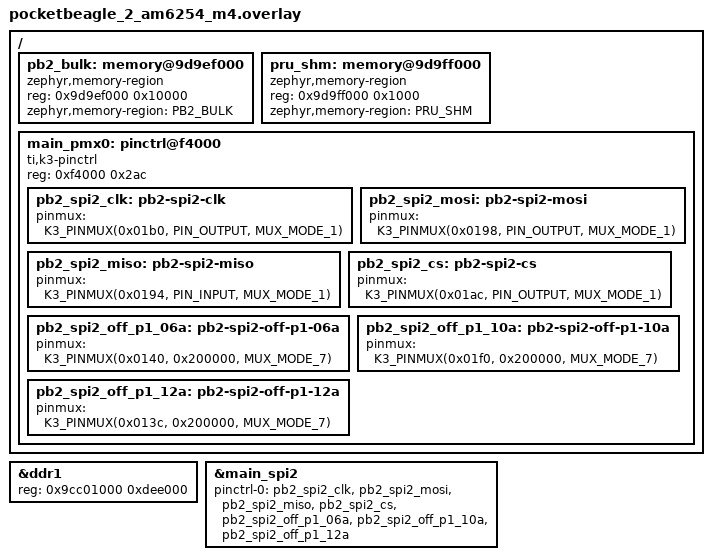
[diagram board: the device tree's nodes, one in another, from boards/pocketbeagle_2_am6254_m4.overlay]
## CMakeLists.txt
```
cmake_minimum_required(VERSION 3.20.0)

find_package(Zephyr REQUIRED HINTS $ENV{ZEPHYR_BASE})

project(pb2_m4 C CXX)

# EmbeddedRPC 1.14.0, cloned by build.sh. It is not used as a Zephyr module:
# that module's Kconfig selects SERIAL from a symbol that depends on the full
# C++ library, and the loop fails configuration. The library sources are
# compiled here,
# with erpc_malloc/erpc_free on the Zephyr heap. Transport is the existing
# OpenAMP RPMsg endpoint, not the module's UART or RPMsg-Lite ports.
set(ERPC ${CMAKE_CURRENT_LIST_DIR}/../../third_party/erpc/erpc_c)

target_include_directories(app PRIVATE
  ${CMAKE_CURRENT_SOURCE_DIR}/../include
  ${CMAKE_CURRENT_SOURCE_DIR}/../erpc/shim
  ${CMAKE_CURRENT_SOURCE_DIR}/src
  ${ERPC}/infra
  ${ERPC}/port
  ${ERPC}/setup
  ${LIBMETAL_INCLUDE_DIR}
  ${OPENAMP_INCLUDE_DIR}
  ${PLATFORM_DIR}
)

target_sources(app PRIVATE
  src/main.c
  src/pb2_service.c
  src/pb2_erpc.cpp
  src/erpc_port_zephyr.cpp
  ../erpc/shim/c_pb2_server.cpp
  ../erpc/shim/pb2_server.cpp
  ../erpc/shim/pb2_interface.cpp
  ${ERPC}/infra/erpc_basic_codec.cpp
  ${ERPC}/infra/erpc_crc16.cpp
  ${ERPC}/infra/erpc_framed_transport.cpp
  ${ERPC}/infra/erpc_message_buffer.cpp
  ${ERPC}/infra/erpc_message_loggers.cpp
  ${ERPC}/infra/erpc_pre_post_action.cpp
  ${ERPC}/infra/erpc_server.cpp
  ${ERPC}/infra/erpc_simple_server.cpp
  ${ERPC}/infra/erpc_utils.cpp
  ${ERPC}/setup/erpc_server_setup.cpp
  ${ERPC}/setup/erpc_setup_mbf_dynamic.cpp
)
```

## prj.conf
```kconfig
CONFIG_KERNEL_BIN_NAME="pb2_m4"
CONFIG_IPM=y
CONFIG_MBOX=y
CONFIG_CPP=y
CONFIG_STD_CPP17=y
CONFIG_REQUIRES_FULL_LIBCPP=y
CONFIG_GLIBCXX_LIBCPP=y
CONFIG_MAIN_STACK_SIZE=2048
CONFIG_HEAP_MEM_POOL_SIZE=8192
CONFIG_SYSTEM_WORKQUEUE_STACK_SIZE=2048
CONFIG_OPENAMP=y
CONFIG_OPENAMP_RSC_TABLE=y
CONFIG_OPENAMP_MASTER=n
CONFIG_OPENAMP_RSC_TABLE_NUM_RPMSG_BUFF=8
CONFIG_LOG=y
CONFIG_LOG_DEFAULT_LEVEL=3
CONFIG_SPI=y
```

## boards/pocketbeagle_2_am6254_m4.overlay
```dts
// SPDX-License-Identifier: MIT
#include <zephyr/dt-bindings/pinctrl/ti-k3-pinctrl.h>

/*
 * Carve the bulk chunk region and the small PRU mailbox out of M4 DDR.
 * ddr1 starts at 0x9cc01000. Bulk is 64 KiB at 0x9d9ef000.
 * Mailbox stays at 0x9d9ff000, matching PB2_SHM_ADDR.
 * Original ddr1 size 0xdff000 ended at 0x9da00000.
 */

&ddr1 {
	reg = <0x9cc01000 0xdee000>;
};

/ {
	pb2_bulk: memory@9d9ef000 {
		compatible = "zephyr,memory-region", "mmio-sram";
		reg = <0x9d9ef000 0x10000>;
		zephyr,memory-region = "PB2_BULK";
	};

	pru_shm: memory@9d9ff000 {
		compatible = "zephyr,memory-region", "mmio-sram";
		reg = <0x9d9ff000 0x1000>;
		zephyr,memory-region = "PRU_SHM";
	};

	/*
	 * Main padcfg at 0xf4000. One pin per group: the K3 pinctrl helper
	 * applies only the first two pinmux cells of each group.
	 * 0x200000 is the pad disable bit used by the Debian kernel's
	 * PIN_DISABLE, OR mux mode 7, so a shorted partner ball stays off.
	 */
	main_pmx0: pinctrl@f4000 {
		compatible = "ti,k3-pinctrl";
		reg = <0xf4000 0x2ac>;
		status = "okay";

		pb2_spi2_clk: pb2-spi2-clk {
			/* P1.08 A20 SPI2_CLK, mode 1 */
			pinmux = <K3_PINMUX(0x01b0, PIN_OUTPUT, MUX_MODE_1)>;
		};
		pb2_spi2_mosi: pb2-spi2-mosi {
			/* P1.12 A19 SPI2_D1 MOSI, mode 1 */
			pinmux = <K3_PINMUX(0x0198, PIN_OUTPUT, MUX_MODE_1)>;
		};
		pb2_spi2_miso: pb2-spi2-miso {
			/* P1.10 B19 SPI2_D0 MISO, mode 1 */
			pinmux = <K3_PINMUX(0x0194, PIN_INPUT, MUX_MODE_1)>;
		};
		pb2_spi2_cs: pb2-spi2-cs {
			/* P1.06 E19 SPI2_CS0, mode 1 */
			pinmux = <K3_PINMUX(0x01ac, PIN_OUTPUT, MUX_MODE_1)>;
		};
		pb2_spi2_off_p1_06a: pb2-spi2-off-p1-06a {
			/* P1.06A AD18, shorted to P1.06 */
			pinmux = <K3_PINMUX(0x0140, 0x200000, MUX_MODE_7)>;
		};
		pb2_spi2_off_p1_10a: pb2-spi2-off-p1-10a {
			/* P1.10 A18, shorted to P1.10 ball B19 */
			pinmux = <K3_PINMUX(0x01f0, 0x200000, MUX_MODE_7)>;
		};
		pb2_spi2_off_p1_12a: pb2-spi2-off-p1-12a {
			/* P1.12A AE18, shorted to P1.12 */
			pinmux = <K3_PINMUX(0x013c, 0x200000, MUX_MODE_7)>;
		};
	};
};

&main_spi2 {
	pinctrl-names = "default";
	pinctrl-0 = <&pb2_spi2_clk &pb2_spi2_mosi &pb2_spi2_miso &pb2_spi2_cs
		     &pb2_spi2_off_p1_06a &pb2_spi2_off_p1_10a &pb2_spi2_off_p1_12a>;
	status = "okay";
};
```

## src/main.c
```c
/*
 * Zephyr on the PocketBeagle 2 M4.
 *
 * Linux calls Zephyr functions over eRPC on RPMsg (channel "rpmsg-raw",
 * address 1024). armPru1 publishes a command in the DDR mailbox at
 * PB2_SHM_ADDR. PRU0 polls that mailbox and arms PRU1.
 */

#include <zephyr/kernel.h>
#include <zephyr/device.h>
#include <zephyr/drivers/ipm.h>
#include <zephyr/drivers/spi.h>
#include <zephyr/sys/printk.h>
#include <zephyr/sys/barrier.h>
#include <zephyr/cache.h>
#include <zephyr/logging/log.h>

#include <errno.h>

#include <openamp/open_amp.h>
#include <metal/sys.h>
#include <metal/io.h>
#include <resource_table.h>
#include <addr_translation.h>

#include "pb2_shm.h"
#include "pb2_erpc.h"

LOG_MODULE_REGISTER(pb2_m4, LOG_LEVEL_INF);

#define RPMSG_CHAN_NAME "rpmsg-raw"
#define RPMSG_CHAN_ADDR 1024

#if CONFIG_IPM_MAX_DATA_SIZE > 0
#define IPM_SEND(dev, w, id, d, s) ipm_send(dev, w, id, d, s)
#else
#define IPM_SEND(dev, w, id, d, s) ipm_send(dev, w, id, NULL, 0)
#endif

#define SHM_NODE       DT_CHOSEN(zephyr_ipc_shm)
#define SHM_START_ADDR DT_REG_ADDR(SHM_NODE)
#define SHM_SIZE       DT_REG_SIZE(SHM_NODE)

#if !DT_HAS_CHOSEN(zephyr_ipc_shm)
#error "M4 board must choose zephyr,ipc_shm"
#endif

static const struct device *const ipm_handle = DEVICE_DT_GET(DT_CHOSEN(zephyr_ipc));

static metal_phys_addr_t shm_physmap = SHM_START_ADDR;
static metal_phys_addr_t rsc_tab_physmap;
static struct metal_io_region shm_io_data;
static struct metal_io_region rsc_io_data;
static struct metal_io_region *shm_io = &shm_io_data;
static struct metal_io_region *rsc_io = &rsc_io_data;
static struct rpmsg_virtio_device rvdev;
static struct rpmsg_device *rpdev;
static struct rpmsg_endpoint ept;
static void *rsc_table;

static K_SEM_DEFINE(mb_sem, 0, 1);

static uint32_t shm_seq;

static volatile struct pb2_shm *const pru_shm =
	(volatile struct pb2_shm *)PB2_SHM_ADDR;

void pb2_shm_publish(const char *cmd)
{
	size_t n = strlen(cmd);

	if (n > sizeof(pru_shm->cmd) - 1) {
		n = sizeof(pru_shm->cmd) - 1;
	}
	memcpy((void *)pru_shm->cmd, cmd, n);
	((volatile char *)pru_shm->cmd)[n] = '\0';
	pru_shm->magic = PB2_SHM_MAGIC;
	barrier_dmem_fence_full();
	pru_shm->seq = ++shm_seq;
	barrier_dmem_fence_full();
	sys_cache_data_flush_range((void *)pru_shm, sizeof(*pru_shm));
	LOG_INF("shm seq %u cmd %s", shm_seq, cmd);
}

static void platform_ipm_callback(const struct device *dev, void *context,
				  uint32_t id, volatile void *data)
{
	ARG_UNUSED(dev);
	ARG_UNUSED(context);
	ARG_UNUSED(id);
	ARG_UNUSED(data);
	k_sem_give(&mb_sem);
}

static int mailbox_notify(void *priv, uint32_t id)
{
	ARG_UNUSED(priv);
	IPM_SEND(ipm_handle, 0, id, &id, 4);
	return 0;
}

static int platform_init(void)
{
	struct metal_init_params metal_params = METAL_INIT_DEFAULTS;
	int rsc_size;
	int status;

	status = metal_init(&metal_params);
	if (status) {
		LOG_ERR("metal_init failed: %d", status);
		return -1;
	}

	metal_io_init(shm_io, (void *)SHM_START_ADDR, &shm_physmap, SHM_SIZE,
		      -1, 0, addr_translation_get_ops(shm_physmap));

	rsc_table_get(&rsc_table, &rsc_size);
	rsc_tab_physmap = (uintptr_t)rsc_table;
	metal_io_init(rsc_io, rsc_table, &rsc_tab_physmap, rsc_size, -1, 0, NULL);

	if (!device_is_ready(ipm_handle)) {
		LOG_ERR("IPM device is not ready");
		return -1;
	}
	ipm_register_callback(ipm_handle, platform_ipm_callback, NULL);
	status = ipm_set_enabled(ipm_handle, 1);
	if (status) {
		LOG_ERR("ipm_set_enabled failed");
		return -1;
	}
	return 0;
}

static struct rpmsg_device *platform_create_rpmsg_vdev(void)
{
	struct fw_rsc_vdev_vring *vring_rsc;
	struct virtio_device *vdev;
	int ret;

	vdev = rproc_virtio_create_vdev(VIRTIO_DEV_DEVICE, VDEV_ID,
					rsc_table_to_vdev(rsc_table),
					rsc_io, NULL, mailbox_notify, NULL);
	if (!vdev) {
		LOG_ERR("failed to create vdev");
		return NULL;
	}

	rproc_virtio_wait_remote_ready(vdev);

	vring_rsc = rsc_table_get_vring0(rsc_table);
	ret = rproc_virtio_init_vring(vdev, 0, vring_rsc->notifyid,
				      (void *)vring_rsc->da, rsc_io,
				      vring_rsc->num, vring_rsc->align);
	if (ret) {
		LOG_ERR("failed to init vring 0");
		goto failed;
	}

	vring_rsc = rsc_table_get_vring1(rsc_table);
	ret = rproc_virtio_init_vring(vdev, 1, vring_rsc->notifyid,
				      (void *)vring_rsc->da, rsc_io,
				      vring_rsc->num, vring_rsc->align);
	if (ret) {
		LOG_ERR("failed to init vring 1");
		goto failed;
	}

	ret = rpmsg_init_vdev(&rvdev, vdev, NULL, shm_io, NULL);
	if (ret) {
		LOG_ERR("failed rpmsg_init_vdev");
		goto failed;
	}
	return rpmsg_virtio_get_rpmsg_device(&rvdev);

failed:
	rproc_virtio_remove_vdev(vdev);
	return NULL;
}

static int rx_cb(struct rpmsg_endpoint *ept_dev, void *data, size_t len,
		 uint32_t src, void *priv)
{
	ARG_UNUSED(ept_dev);
	ARG_UNUSED(src);
	ARG_UNUSED(priv);

	pb2_erpc_push(data, len);
	return RPMSG_SUCCESS;
}

int pb2_rpmsg_tx(const void *data, size_t len)
{
	int ret = rpmsg_send(&ept, (void *)data, len);

	return ret < 0 ? -1 : 0;
}

static void app_thread(void *a, void *b, void *c)
{
	ARG_UNUSED(a);
	ARG_UNUSED(b);
	ARG_UNUSED(c);

	pb2_erpc_server();
}

static void rpmsg_thread(void *a, void *b, void *c)
{
	ARG_UNUSED(a);
	ARG_UNUSED(b);
	ARG_UNUSED(c);

	if (platform_init()) {
		return;
	}
	rpdev = platform_create_rpmsg_vdev();
	if (!rpdev) {
		return;
	}

	if (rpmsg_create_ept(&ept, rpdev, RPMSG_CHAN_NAME, RPMSG_CHAN_ADDR,
			     RPMSG_ADDR_ANY, rx_cb, NULL)) {
		LOG_ERR("rpmsg_create_ept failed");
		return;
	}
	LOG_INF("rpmsg channel %s addr %d is up", RPMSG_CHAN_NAME, RPMSG_CHAN_ADDR);

	while (1) {
		k_sem_take(&mb_sem, K_FOREVER);
		rproc_virtio_notified(rvdev.vdev, VRING1_ID);
	}
}

K_THREAD_DEFINE(rpmsg_tid, 4096, rpmsg_thread, NULL, NULL, NULL, K_PRIO_COOP(8), 0, 0);
K_THREAD_DEFINE(app_tid, 8192, app_thread, NULL, NULL, NULL, K_PRIO_COOP(7), 0, 0);

int pb2_spi2_write(const void *buf, size_t len)
{
	static const struct spi_config cfg = {
		.frequency = 1000000,
		.operation = SPI_OP_MODE_MASTER | SPI_WORD_SET(8) | SPI_TRANSFER_MSB,
		.peripheral = 0,
	};
	const struct device *spi = DEVICE_DT_GET(DT_NODELABEL(main_spi2));
	const struct spi_buf txb = {
		.buf = (void *)buf,
		.len = len,
	};
	const struct spi_buf_set tx = {
		.buffers = &txb,
		.count = 1,
	};

	if (!buf || !len) {
		return -EINVAL;
	}
	if (!device_is_ready(spi)) {
		LOG_ERR("spi2 not ready");
		return -ENODEV;
	}
	return spi_write(spi, &cfg, &tx);
}

static void pb2_spi_hello(void)
{
	static const uint8_t hello[] = {'h', 'e', 'l', 'l', 'o'};
	int ret = pb2_spi2_write(hello, sizeof(hello));
	char msg[56];

	if (ret == -ENODEV) {
		pb2_shm_publish("spi hello not ready");
		return;
	}
	if (ret) {
		LOG_ERR("spi2 hello failed: %d", ret);
		snprintk(msg, sizeof(msg), "spi hello fail %d", ret);
		pb2_shm_publish(msg);
		return;
	}
	LOG_INF("spi2 hello wrote %u bytes", (unsigned int)sizeof(hello));
	pb2_shm_publish("spi hello ok");
}

int main(void)
{
	pb2_shm_publish("hello from zephyr");
	LOG_INF("pb2 m4 hello, shm seq %u", shm_seq);
	pb2_spi_hello();
	return 0;
}
```

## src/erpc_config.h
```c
/* SPDX-License-Identifier: MIT */
#ifndef _ERPC_CONFIG_H_
#define _ERPC_CONFIG_H_

#define ERPC_ALLOCATION_POLICY_DYNAMIC (0U)
#define ERPC_ALLOCATION_POLICY_STATIC (1U)
#define ERPC_THREADS_NONE (0U)
#define ERPC_THREADS_PTHREADS (1U)
#define ERPC_THREADS_FREERTOS (2U)
#define ERPC_THREADS_ZEPHYR (3U)
#define ERPC_THREADS_MBED (4U)
#define ERPC_THREADS_WIN32 (5U)
#define ERPC_THREADS_THREADX (6U)
#define ERPC_NOEXCEPT_DISABLED (0U)
#define ERPC_NOEXCEPT_ENABLED (1U)
#define ERPC_NESTED_CALLS_DISABLED (0U)
#define ERPC_NESTED_CALLS_ENABLED (1U)
#define ERPC_NESTED_CALLS_DETECTION_DISABLED (0U)
#define ERPC_NESTED_CALLS_DETECTION_ENABLED (1U)
#define ERPC_MESSAGE_LOGGING_DISABLED (0U)
#define ERPC_MESSAGE_LOGGING_ENABLED (1U)
#define ERPC_TRANSPORT_MU_USE_MCMGR_DISABLED (0U)
#define ERPC_TRANSPORT_MU_USE_MCMGR_ENABLED (1U)
#define ERPC_PRE_POST_ACTION_DISABLED (0U)
#define ERPC_PRE_POST_ACTION_ENABLED (1U)
#define ERPC_PRE_POST_ACTION_DEFAULT_DISABLED (0U)
#define ERPC_PRE_POST_ACTION_DEFAULT_ENABLED (1U)

/* The RPMsg callback feeds a byte queue. The server thread blocks on that. */
#define ERPC_THREADS (ERPC_THREADS_NONE)
#define ERPC_DEFAULT_BUFFER_SIZE (512U)
#define ERPC_NOEXCEPT (ERPC_NOEXCEPT_DISABLED)
#define ERPC_NESTED_CALLS (ERPC_NESTED_CALLS_DISABLED)
#define ERPC_NESTED_CALLS_DETECTION (ERPC_NESTED_CALLS_DETECTION_DISABLED)
#define ERPC_MESSAGE_LOGGING (ERPC_MESSAGE_LOGGING_DISABLED)
#define ERPC_PRE_POST_ACTION (ERPC_PRE_POST_ACTION_DISABLED)
#define ERPC_PRE_POST_ACTION_DEFAULT (ERPC_PRE_POST_ACTION_DEFAULT_DISABLED)

#endif
```

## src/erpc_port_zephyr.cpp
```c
/* SPDX-License-Identifier: MIT */
/*
 * eRPC allocator for the M4. Zephyr's minimal C++ library already provides
 * operator new, so this file only maps erpc_malloc/erpc_free onto k_malloc.
 */

#include <zephyr/kernel.h>

#include "erpc_port.h"

void *erpc_malloc(size_t size)
{
	return k_malloc(size);
}

void erpc_free(void *ptr)
{
	k_free(ptr);
}
```

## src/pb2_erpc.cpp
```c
/* SPDX-License-Identifier: MIT */
/*
 * eRPC server over the existing OpenAMP RPMsg endpoint.
 * One RPMsg message is a slice of an eRPC frame. Frames are small.
 */

#include "erpc_framed_transport.hpp"
#include "erpc_server_setup.h"
#include "erpc_mbf_setup.h"

#include <zephyr/kernel.h>
#include <zephyr/logging/log.h>
#include <string.h>

extern "C" {
#include "c_pb2_server.h"
#include "pb2_erpc.h"
}

LOG_MODULE_DECLARE(pb2_m4, LOG_LEVEL_INF);

static K_SEM_DEFINE(rx_sem, 0, 16);
static uint8_t rx_buf[1024];
static size_t rx_len;

extern "C" void pb2_erpc_push(const void *data, size_t len)
{
	const uint8_t *src = static_cast<const uint8_t *>(data);
	unsigned int key = irq_lock();
	size_t space = sizeof(rx_buf) - rx_len;

	if (len > space) {
		len = space;
	}
	memcpy(rx_buf + rx_len, src, len);
	rx_len += len;
	irq_unlock(key);
	k_sem_give(&rx_sem);
}

class RpmsgTransport : public erpc::FramedTransport {
protected:
	erpc_status_t underlyingSend(const uint8_t *data, uint32_t size) override
	{
		while (size) {
			uint32_t n = size > 480u ? 480u : size;

			if (pb2_rpmsg_tx(data, n) != 0) {
				return kErpcStatus_SendFailed;
			}
			data += n;
			size -= n;
		}
		return kErpcStatus_Success;
	}

	erpc_status_t underlyingReceive(uint8_t *data, uint32_t size) override
	{
		uint32_t got = 0;

		while (got < size) {
			unsigned int key = irq_lock();
			size_t n = rx_len;

			if (n > size - got) {
				n = size - got;
			}
			if (n) {
				memcpy(data + got, rx_buf, n);
				memmove(rx_buf, rx_buf + n, rx_len - n);
				rx_len -= n;
				got += static_cast<uint32_t>(n);
			}
			irq_unlock(key);
			if (got >= size) {
				break;
			}
			k_sem_take(&rx_sem, K_FOREVER);
		}
		return kErpcStatus_Success;
	}
};

extern "C" void pb2_erpc_server(void)
{
	RpmsgTransport transport;
	erpc_mbf_t mbf = erpc_mbf_dynamic_init();
	erpc_server_t server = erpc_server_init(reinterpret_cast<erpc_transport_t>(&transport), mbf);
	erpc_service_t service = create_Pb2Service_service();

	if (!server || !service) {
		LOG_ERR("eRPC server init failed");
		return;
	}
	erpc_add_service_to_server(server, service);
	LOG_INF("eRPC server waiting on rpmsg");
	while (1) {
		erpc_status_t status = erpc_server_poll(server);

		if (status != kErpcStatus_Success) {
			LOG_ERR("eRPC poll status %d", (int)status);
		}
	}
}
```

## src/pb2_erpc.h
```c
/* SPDX-License-Identifier: MIT */
#ifndef PB2_ERPC_H_
#define PB2_ERPC_H_

#include <stddef.h>

void pb2_shm_publish(const char *cmd);
int pb2_spi2_write(const void *buf, size_t len);
int pb2_rpmsg_tx(const void *data, size_t len);
void pb2_erpc_push(const void *data, size_t len);
void pb2_erpc_server(void);

#endif
```

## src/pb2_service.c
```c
/* SPDX-License-Identifier: MIT */
/*
 * Functions Linux calls through Zephyr eRPC.
 * arm_pru1 asks PRU0, via the small mailbox, to arm PRU1.
 * take_chunk checks a bulk buffer Linux already wrote.
 */

#include <zephyr/kernel.h>
#include <zephyr/cache.h>
#include <zephyr/logging/log.h>

#include <stdint.h>
#include <stdio.h>
#include <string.h>

#include "pb2_erpc.h"
#include "pb2_shm.h"

LOG_MODULE_DECLARE(pb2_m4, LOG_LEVEL_INF);

static volatile struct pb2_bulk *const bulk =
	(volatile struct pb2_bulk *)PB2_BULK_ADDR;

char *say(const char *msg)
{
	size_t n;
	char *out;

	if (!msg) {
		msg = "";
	}
	n = strlen(msg);
	if (n > 160) {
		n = 160;
	}
	out = k_malloc(n + 16);
	if (!out) {
		return NULL;
	}
	snprintf(out, n + 16, "zephyr: %.*s", (int)n, msg);
	LOG_INF("erpc say: %s", out);
	return out;
}

char *spiWrite(const char *text)
{
	static const uint8_t hello[] = {'h', 'e', 'l', 'l', 'o'};
	uint8_t buf[256];
	const uint8_t *src;
	size_t n;
	int ret;
	char *out;

	if (!text || !text[0]) {
		src = hello;
		n = sizeof(hello);
	} else {
		n = strlen(text);
		if (n > sizeof(buf)) {
			n = sizeof(buf);
		}
		memcpy(buf, text, n);
		src = buf;
	}
	ret = pb2_spi2_write(src, n);
	out = k_malloc(64);
	if (!out) {
		return NULL;
	}
	if (ret) {
		snprintf(out, 64, "zephyr: spi wrote 0 bytes");
		LOG_ERR("erpc spi fail %d", ret);
		return out;
	}
	snprintf(out, 64, "zephyr: spi wrote %u bytes", (unsigned int)n);
	LOG_INF("%s", out);
	return out;
}

int32_t armPru1(uint32_t period_cycles, uint32_t periods)
{
	char cmd[56];

	snprintf(cmd, sizeof(cmd), "arm %u %u", period_cycles, periods);
	pb2_shm_publish(cmd);
	LOG_INF("erpc arm pru1 period %u count %u", period_cycles, periods);
	return 0;
}

int32_t sendXy(uint32_t x, uint32_t y)
{
	char cmd[56];

	snprintf(cmd, sizeof(cmd), "xy %u %u", x, y);
	pb2_shm_publish(cmd);
	LOG_INF("erpc xy x %u y %u", x, y);
	return 0;
}

uint32_t takeChunk(uint32_t seq, uint32_t length, uint32_t crc)
{
	uint32_t got;
	uint32_t magic;
	uint32_t got_seq;
	uint32_t got_len;
	uint32_t got_crc;

	if (length > sizeof(bulk->data)) {
		return 0;
	}
	sys_cache_data_invd_range((void *)bulk, 16u + length);
	magic = bulk->magic;
	got_seq = bulk->seq;
	got_len = bulk->length;
	got_crc = bulk->crc;
	if (magic != PB2_BULK_MAGIC || got_seq != seq || got_len != length ||
	    got_crc != crc) {
		LOG_INF("chunk mismatch magic %08x seq %u len %u crc %08x",
			magic, got_seq, got_len, got_crc);
		return 0;
	}
	got = pb2_crc32((const uint8_t *)bulk->data, length);
	LOG_INF("chunk seq %u len %u crc %08x", seq, length, got);
	return got;
}
```
